# STM32F410 register map
File version: 1.1
CPU: CM4 r1p0, little endian, no MPU, no FPU, 3 interrupt priority bits
Registers are 32-bit, read-write, reset 0x0 unless marked. A register's access mark holds for its fields unless they carry their own. Offsets are from the block's base; lines under a group give offsets from that group; [hi:lo] are bit positions; {n}, {i} and the like mark numbered series; 'fields as' and 'values as' point back to an identical list; <NAME> marks a mode.

## Memory map
0xE000ED00 SCB size 0x41 — System control block
0xE000ED88 FPU_CPACR size 0x5 — Floating point unit CPACR
0xE000EDF0 CoreDebug size 0x10

## CoreDebug
Base 0xE000EDF0; register names take the prefix CoreDebug_
0x00 DHCSR access not given — Debug Halting Control and Status Register
  [25] S_RESET_ST ro, [24] S_RETIRE_ST ro, [19] S_LOCKUP ro, [18] S_SLEEP ro, [17] S_HALT ro, [16] S_REGRDY ro, [31:16] DBGKEY wo, [5] C_SNAPSTALL, [3] C_MASKINTS, [2] C_STEP, [1] C_HALT, [0] C_DEBUGEN
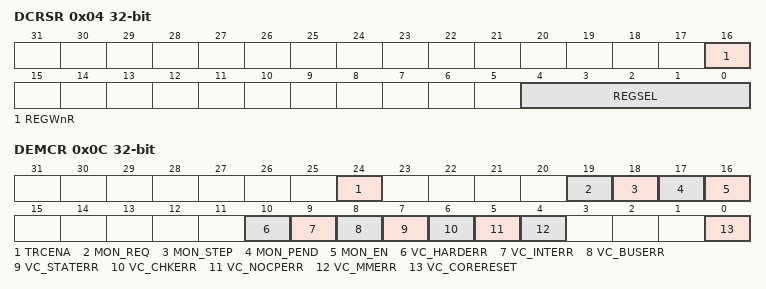
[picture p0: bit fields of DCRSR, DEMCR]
0x04 DCRSR wo — Debug Core Register Selector Register
  [16] REGWnR, [4:0] REGSEL
0x08 DCRDR access not given — Debug Core Register Data Register
0x0C DEMCR access not given — Debug Exception and Monitor Control Register
  [24] TRCENA, [19] MON_REQ, [18] MON_STEP, [17] MON_PEND, [16] MON_EN, [10] VC_HARDERR, [9] VC_INTERR, [8] VC_BUSERR, [7] VC_STATERR, [6] VC_CHKERR, [5] VC_NOCPERR, [4] VC_MMERR, [0] VC_CORERESET

## SCB — System control block
Base 0xE000ED00
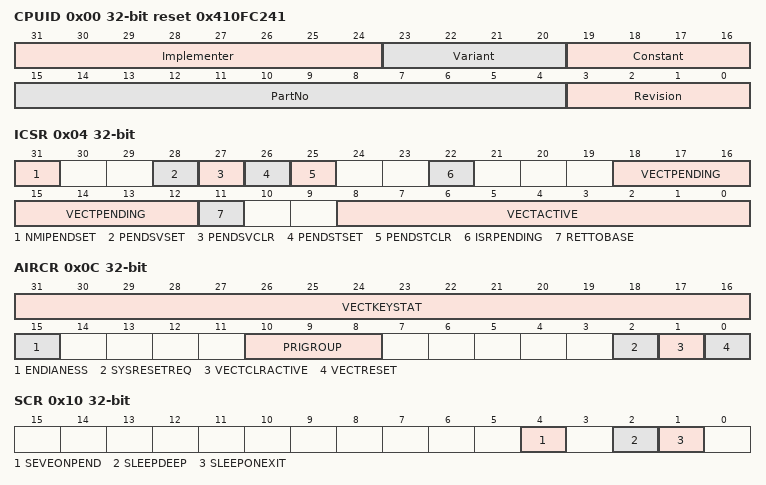
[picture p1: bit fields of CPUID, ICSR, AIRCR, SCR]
0x00 CPUID ro reset 0x410FC241 — CPUID base register
  [31:24] Implementer — Implementer code
  [23:20] Variant — Variant number
  [19:16] Constant — Reads as 0xF
  [15:4] PartNo — Part number of the processor
  [3:0] Revision — Revision number
0x04 ICSR — Interrupt control and state register
  [31] NMIPENDSET — NMI set-pending bit.
  [28] PENDSVSET — PendSV set-pending bit
  [27] PENDSVCLR — PendSV clear-pending bit
  [26] PENDSTSET — SysTick exception set-pending bit
  [25] PENDSTCLR — SysTick exception clear-pending bit
  [22] ISRPENDING — Interrupt pending flag
  [18:12] VECTPENDING — Pending vector
  [11] RETTOBASE — Return to base level
  [8:0] VECTACTIVE — Active vector
0x08 VTOR — Vector table offset register
  [29:9] TBLOFF — Vector table base offset field
0x0C AIRCR — Application interrupt and reset control register
  [31:16] VECTKEYSTAT — Register key
  [15] ENDIANESS
  [10:8] PRIGROUP
  [2] SYSRESETREQ
  [1] VECTCLRACTIVE
  [0] VECTRESET
0x10 SCR — System control register
  [4] SEVEONPEND — Send Event on Pending bit
  [2] SLEEPDEEP
  [1] SLEEPONEXIT
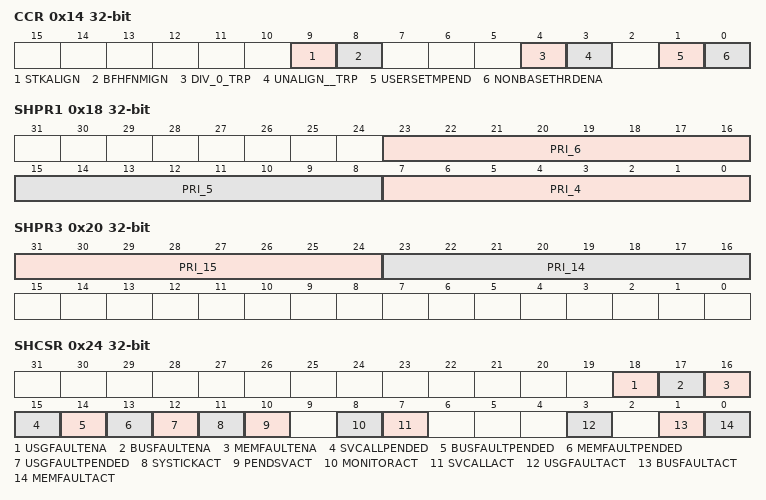
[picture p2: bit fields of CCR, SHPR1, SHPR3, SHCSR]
0x14 CCR — Configuration and control register
  [9] STKALIGN
  [8] BFHFNMIGN
  [4] DIV_0_TRP
  [3] UNALIGN__TRP
  [1] USERSETMPEND
  [0] NONBASETHRDENA — Configures how the processor enters Thread mode
0x18 SHPR1 — System handler priority registers
  [23:16] PRI_6 — Priority of system handler 6
  [15:8] PRI_5 — Priority of system handler 5
  [7:0] PRI_4 — Priority of system handler 4
0x1C SHPR2 — System handler priority registers
  [31:24] PRI_11 — Priority of system handler 11
0x20 SHPR3 — System handler priority registers
  [31:24] PRI_15 — Priority of system handler 15
  [23:16] PRI_14 — Priority of system handler 14
0x24 SHCSR — System handler control and state register
  [18] USGFAULTENA — Usage fault enable bit
  [17] BUSFAULTENA — Bus fault enable bit
  [16] MEMFAULTENA — Memory management fault enable bit
  [15] SVCALLPENDED — SVC call pending bit
  [14] BUSFAULTPENDED — Bus fault exception pending bit
  [13] MEMFAULTPENDED — Memory management fault exception pending bit
  [12] USGFAULTPENDED — Usage fault exception pending bit
  [11] SYSTICKACT — SysTick exception active bit
  [10] PENDSVACT — PendSV exception active bit
  [8] MONITORACT — Debug monitor active bit
  [7] SVCALLACT — SVC call active bit
  [3] USGFAULTACT — Usage fault exception active bit
  [1] BUSFAULTACT — Bus fault exception active bit
  [0] MEMFAULTACT — Memory management fault exception active bit
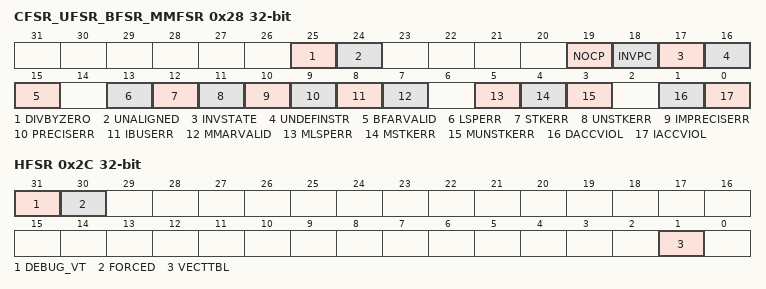
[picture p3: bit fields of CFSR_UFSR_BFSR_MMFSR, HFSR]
0x28 CFSR_UFSR_BFSR_MMFSR — Configurable fault status register
  [25] DIVBYZERO — Divide by zero usage fault
  [24] UNALIGNED — Unaligned access usage fault
  [19] NOCP — No coprocessor usage fault.
  [18] INVPC — Invalid PC load usage fault
  [17] INVSTATE — Invalid state usage fault
  [16] UNDEFINSTR — Undefined instruction usage fault
  [15] BFARVALID — Bus Fault Address Register (BFAR) valid flag
  [13] LSPERR — Bus fault on floating-point lazy state preservation
  [12] STKERR — Bus fault on stacking for exception entry
  [11] UNSTKERR — Bus fault on unstacking for a return from exception
  [10] IMPRECISERR — Imprecise data bus error
  [9] PRECISERR — Precise data bus error
  [8] IBUSERR — Instruction bus error
  [7] MMARVALID — Memory Management Fault Address Register (MMAR) valid flag
  [5] MLSPERR
  [4] MSTKERR — Memory manager fault on stacking for exception entry.
  [3] MUNSTKERR — Memory manager fault on unstacking for a return from exception
  [1] DACCVIOL — Data access violation flag
  [0] IACCVIOL — Instruction access violation flag
0x2C HFSR — Hard fault status register
  [31] DEBUG_VT — Reserved for Debug use
  [30] FORCED — Forced hard fault
  [1] VECTTBL — Vector table hard fault
0x34 MMFAR — Memory management fault address register
  [31:0] MMFAR — Memory management fault address
0x38 BFAR — Bus fault address register
  [31:0] BFAR — Bus fault address
0x3C AFSR — Auxiliary fault status register
  [31:0] IMPDEF — Implementation defined

## FPU_CPACR — Floating point unit CPACR
Base 0xE000ED88
0x00 CPACR — Coprocessor access control register
  [23:20] CP
